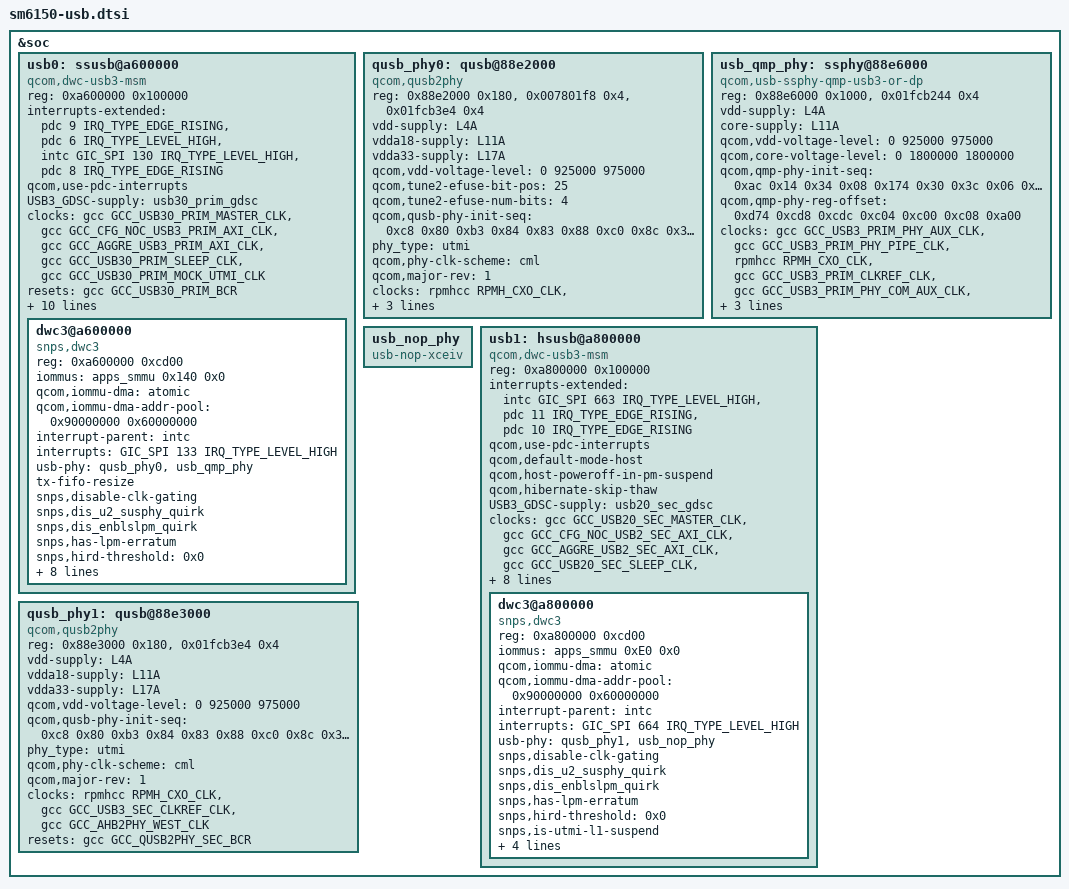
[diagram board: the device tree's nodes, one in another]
#include <dt-bindings/clock/qcom,gcc-sm6150.h>
#include <dt-bindings/phy/qcom,sm8150-qmp-usb3.h>

&soc {
	/* Primary USB port related controller */
	usb0: ssusb@a600000 {
		compatible = "qcom,dwc-usb3-msm";
		reg = <0xa600000 0x100000>;
		reg-names = "core_base";

		#address-cells = <1>;
		#size-cells = <1>;
		ranges;

		interrupts-extended = <&pdc 9 IRQ_TYPE_EDGE_RISING>,
				<&pdc 6 IRQ_TYPE_LEVEL_HIGH>,
				<&intc GIC_SPI 130 IRQ_TYPE_LEVEL_HIGH>,
				<&pdc 8 IRQ_TYPE_EDGE_RISING>;
		interrupt-names = "dp_hs_phy_irq", "ss_phy_irq",
				"pwr_event_irq", "dm_hs_phy_irq";
		qcom,use-pdc-interrupts;

		USB3_GDSC-supply = <&usb30_prim_gdsc>;
		clocks = <&gcc  GCC_USB30_PRIM_MASTER_CLK>,
			<&gcc GCC_CFG_NOC_USB3_PRIM_AXI_CLK>,
			<&gcc GCC_AGGRE_USB3_PRIM_AXI_CLK>,
			<&gcc GCC_USB30_PRIM_SLEEP_CLK>,
			<&gcc GCC_USB30_PRIM_MOCK_UTMI_CLK>;
		clock-names = "core_clk", "iface_clk", "bus_aggr_clk",
				"sleep_clk", "utmi_clk";

		resets = <&gcc GCC_USB30_PRIM_BCR>;
		reset-names = "core_reset";

		qcom,core-clk-rate = <200000000>;
		qcom,core-clk-rate-hs = <66666667>;
		qcom,dwc-usb3-msm-tx-fifo-size = <21288>;
		qcom,host-poweroff-in-pm-suspend;
		qcom,hibernate-skip-thaw;
		qcom,disable-host-ssphy-powerdown;
		interconnect-names = "usb-ddr", "ddr-usb";
		interconnects = <&aggre1_noc MASTER_USB3_0 &mc_virt SLAVE_EBI1>,
				<&gem_noc MASTER_APPSS_PROC &config_noc SLAVE_USB3>;

		dwc3@a600000 {
			compatible = "snps,dwc3";
			reg = <0xa600000 0xcd00>;
			iommus = <&apps_smmu 0x140 0x0>;
			qcom,iommu-dma = "atomic";
			qcom,iommu-dma-addr-pool = <0x90000000 0x60000000>;
			interrupt-parent = <&intc>;
			interrupts = <GIC_SPI 133 IRQ_TYPE_LEVEL_HIGH>;
			usb-phy = <&qusb_phy0>, <&usb_qmp_phy>;
			tx-fifo-resize;
			snps,disable-clk-gating;
			snps,dis_u2_susphy_quirk;
			snps,dis_enblslpm_quirk;
			snps,has-lpm-erratum;
			snps,hird-threshold = /bits/ 8 <0x0>;
			snps,is-utmi-l1-suspend;
			snps,usb2-gadget-lpm-disable;
			snps,dis-u1-entry-quirk;
			snps,dis-u2-entry-quirk;
			snps,usb3_lpm_capable;
			maximum-speed = "high-speed";
			dr_mode = "otg";
			usb-role-switch;
		};
	};

	/* Primary USB port related High Speed PHY */
	qusb_phy0: qusb@88e2000 {
		compatible = "qcom,qusb2phy";
		reg = <0x88e2000 0x180>,
			<0x007801f8 0x4>,
			<0x01fcb3e4 0x4>;
		reg-names = "qusb_phy_base",
			"tune2_efuse_addr",
			"tcsr_conn_box_spare_0";

		vdd-supply = <&L4A>;
		vdda18-supply = <&L11A>;
		vdda33-supply = <&L17A>;
		qcom,vdd-voltage-level = <0 925000 975000>;
		qcom,tune2-efuse-bit-pos = <25>;
		qcom,tune2-efuse-num-bits = <4>;
		qcom,qusb-phy-init-seq = <0xc8 0x80
					0xb3 0x84
					0x83 0x88
					0xc0 0x8c
					0x30 0x08
					0x79 0x0c
					0x21 0x10
					0x14 0x9c
					0x9f 0x1c
					0x00 0x18>;
		phy_type = "utmi";
		qcom,phy-clk-scheme = "cml";
		qcom,major-rev = <1>;

		/* USB2PHY gets clock directly from CXO pad
		 * connected to differential pin cxo_core_in_1p8_vdda.
		 */
		clocks = <&rpmhcc RPMH_CXO_CLK>,
			<&gcc GCC_USB3_PRIM_CLKREF_CLK>,
			<&gcc GCC_AHB2PHY_WEST_CLK>;
		clock-names =  "ref_clk_src","ref_clk", "cfg_ahb_clk";

		resets = <&gcc GCC_QUSB2PHY_PRIM_BCR>;
		reset-names = "phy_reset";
	};

	/* Primary USB port related QMP USB PHY */
	usb_qmp_phy: ssphy@88e6000 {
		compatible = "qcom,usb-ssphy-qmp-usb3-or-dp";
		reg = <0x88e6000 0x1000>,
			<0x01fcb244 0x4>;
		reg-names = "qmp_phy_base",
			"vls_clamp_reg";

		vdd-supply = <&L4A>;
		core-supply = <&L11A>;
		qcom,vdd-voltage-level = <0 925000 975000>;
		qcom,core-voltage-level = <0 1800000 1800000>;
		qcom,qmp-phy-init-seq =
			/* <reg_offset, value, delay> */

				<0xac  0x14
				 0x34  0x08
				 0x174 0x30
				 0x3c  0x06
				 0xb4  0x00
				 0xb8  0x08
				 0x70  0x0f
				 0x19c 0x01
				 0x178 0x00
				 0xd0  0x82
				 0xdc  0x55
				 0xe0  0x55
				 0xe4  0x03
				 0x78  0x0b
				 0x84  0x16
				 0x90  0x28
				 0x108 0x80
				 0x10c 0x00
				 0x184 0x0a
				 0x4c  0x15
				 0x50  0x34
				 0x54  0x00
				 0xc8  0x00
				 0x18c 0x00
				 0xcc  0x00
				 0x128 0x00
				 0x0c  0x0a
				 0x10  0x01
				 0x1c  0x31
				 0x20  0x01
				 0x14  0x00
				 0x18  0x00
				 0x24  0xde
				 0x28  0x07
				 0x48  0x0f
				 0x194 0x06
				 0x100 0x80
				 0xa8  0x01
				 0x430 0x0b
				 0x830 0x0b
				 0x444 0x00
				 0x844 0x00
				 0x43c 0x00
				 0x83c 0x00
				 0x440 0x00
				 0x840 0x00
				 0x408 0x0a
				 0x808 0x0a
				 0x414 0x06
				 0x814 0x06
				 0x434 0x75
				 0x834 0x75
				 0x4d4 0x02
				 0x8d4 0x02
				 0x4d8 0x4e
				 0x8d8 0x4e
				 0x4dc 0x18
				 0x8dc 0x18
				 0x4f8 0x77
				 0x8f8 0x77
				 0x4fc 0x80
				 0x8fc 0x80
				 0x4c0 0x0a
				 0x8c0 0x0a
				 0x504 0x03
				 0x904 0x03
				 0x50c 0x16
				 0x90c 0x16
				 0x500 0x00
				 0x900 0x00
				 0x564 0x00
				 0x964 0x00
				 0x260 0x10
				 0x660 0x10
				 0x2a4 0x12
				 0x6a4 0x12
				 0x28c 0xc6
				 0x68c 0xc6
				 0x244 0x00
				 0x644 0x00
				 0x248 0x00
				 0x648 0x00
				 0xc0c 0x9f
				 0xc24 0x17
				 0xc28 0x0f
				 0xcc8 0x83
				 0xcc4 0x02
				 0xccc 0x09
				 0xcd0 0xa2
				 0xcd4 0x85
				 0xc80 0xd1
				 0xc84 0x1f
				 0xc88 0x47
				 0xcb8 0x75
				 0xcbc 0x13
				 0xcb0 0x86
				 0xca0 0x04
				 0xc8c 0x44
				 0xc70 0xe7
				 0xc74 0x03
				 0xc78 0x40
				 0xc7c 0x00
				 0xdd8 0x88>;

		qcom,qmp-phy-reg-offset =
				<0xd74 /* USB3_PHY_PCS_STATUS */
				 0xcd8 /* USB3_PHY_AUTONOMOUS_MODE_CTRL */
				 0xcdc /* USB3_PHY_LFPS_RXTERM_IRQ_CLEAR */
				 0xc04 /* USB3_PHY_POWER_DOWN_CONTROL */
				 0xc00 /* USB3_PHY_SW_RESET */
				 0xc08 /* USB3_PHY_START */
				 0xa00>; /* USB3PHY_PCS_MISC_TYPEC_CTRL */

		clocks = <&gcc GCC_USB3_PRIM_PHY_AUX_CLK>,
			<&gcc GCC_USB3_PRIM_PHY_PIPE_CLK>,
			<&rpmhcc RPMH_CXO_CLK>,
			<&gcc GCC_USB3_PRIM_CLKREF_CLK>,
			<&gcc GCC_USB3_PRIM_PHY_COM_AUX_CLK>,
			<&gcc GCC_AHB2PHY_WEST_CLK>;

		clock-names = "aux_clk", "pipe_clk", "ref_clk_src",
				"ref_clk", "com_aux_clk", "cfg_ahb_clk";

		resets = <&gcc GCC_USB3_PHY_PRIM_SP0_BCR>,
			<&gcc GCC_USB3PHY_PHY_PRIM_SP0_BCR>;
		reset-names = "phy_reset", "phy_phy_reset";
	};

	usb_nop_phy: usb_nop_phy {
		compatible = "usb-nop-xceiv";
	};

	/* Secondary USB port related controller */
	usb1: hsusb@a800000 {
		compatible = "qcom,dwc-usb3-msm";
		reg = <0xa800000 0x100000>;
		reg-names = "core_base";

		#address-cells = <1>;
		#size-cells = <1>;
		ranges;

		interrupts-extended = <&intc GIC_SPI 663 IRQ_TYPE_LEVEL_HIGH>,
				<&pdc 11 IRQ_TYPE_EDGE_RISING>,
				<&pdc 10 IRQ_TYPE_EDGE_RISING>;
		interrupt-names = "pwr_event_irq", "dp_hs_phy_irq",
				"dm_hs_phy_irq";
		qcom,use-pdc-interrupts;

		qcom,default-mode-host;
		qcom,host-poweroff-in-pm-suspend;
		qcom,hibernate-skip-thaw;

		USB3_GDSC-supply = <&usb20_sec_gdsc>;
		clocks = <&gcc  GCC_USB20_SEC_MASTER_CLK>,
			<&gcc GCC_CFG_NOC_USB2_SEC_AXI_CLK>,
			<&gcc GCC_AGGRE_USB2_SEC_AXI_CLK>,
			<&gcc GCC_USB20_SEC_SLEEP_CLK>,
			<&gcc GCC_USB20_SEC_MOCK_UTMI_CLK>;
		clock-names = "core_clk", "iface_clk", "bus_aggr_clk",
				"sleep_clk", "utmi_clk";

		resets = <&gcc GCC_USB20_SEC_BCR>;
		reset-names = "core_reset";

		qcom,core-clk-rate = <120000000>;
		qcom,core-clk-rate-hs = <66666667>;

		interconnect-names = "usb-ddr", "ddr-usb";
		interconnects = <&aggre1_noc MASTER_USB2 &mc_virt SLAVE_EBI1>,
				<&gem_noc MASTER_APPSS_PROC &config_noc SLAVE_USB2>;

		dwc3@a800000 {
			compatible = "snps,dwc3";
			reg = <0xa800000 0xcd00>;
			iommus = <&apps_smmu 0xE0 0x0>;
			qcom,iommu-dma = "atomic";
			qcom,iommu-dma-addr-pool = <0x90000000 0x60000000>;
			interrupt-parent = <&intc>;
			interrupts = <GIC_SPI 664 IRQ_TYPE_LEVEL_HIGH>;
			usb-phy = <&qusb_phy1>, <&usb_nop_phy>;
			snps,disable-clk-gating;
			snps,dis_u2_susphy_quirk;
			snps,dis_enblslpm_quirk;
			snps,has-lpm-erratum;
			snps,hird-threshold = /bits/ 8 <0x0>;
			snps,is-utmi-l1-suspend;
			snps,usb2-gadget-lpm-disable;
			maximum-speed = "high-speed";
			dr_mode = "otg";
			usb-role-switch;
		};
	};

	/* Secondary USB port related High Speed PHY */
	qusb_phy1: qusb@88e3000 {
		compatible = "qcom,qusb2phy";
		reg = <0x88e3000 0x180>,
			<0x01fcb3e4 0x4>;
		reg-names = "qusb_phy_base",
			"tcsr_conn_box_spare_0";

		vdd-supply = <&L4A>;
		vdda18-supply = <&L11A>;
		vdda33-supply = <&L17A>;
		qcom,vdd-voltage-level = <0 925000 975000>;
		qcom,qusb-phy-init-seq = <0xc8 0x80
					0xb3 0x84
					0x83 0x88
					0xc0 0x8c
					0x30 0x08
					0x79 0x0c
					0x21 0x10
					0x14 0x9c
					0x9f 0x1c
					0x00 0x18>;
		phy_type = "utmi";
		qcom,phy-clk-scheme = "cml";
		qcom,major-rev = <1>;

		/* USB2PHY gets clock directly from CXO pad
		 * connected to differential pin cxo_core_in_1p8_vdda.
		 */
		clocks = <&rpmhcc RPMH_CXO_CLK>,
			<&gcc GCC_USB3_SEC_CLKREF_CLK>,
			<&gcc GCC_AHB2PHY_WEST_CLK>;
		clock-names =  "ref_clk_src","ref_clk", "cfg_ahb_clk";

		resets = <&gcc GCC_QUSB2PHY_SEC_BCR>;
		reset-names = "phy_reset";
	};
};
